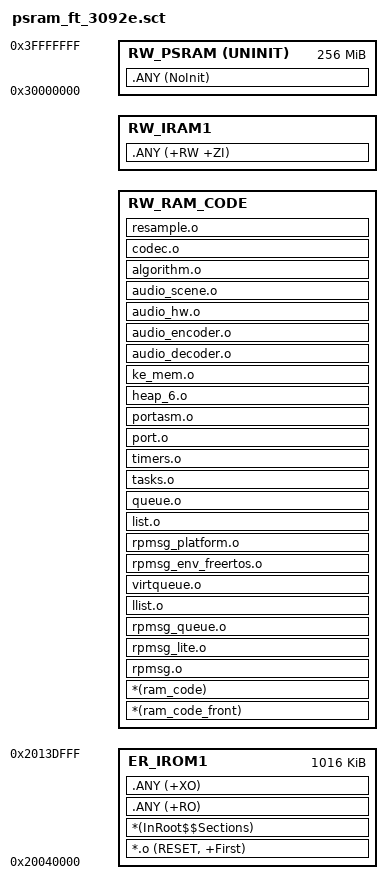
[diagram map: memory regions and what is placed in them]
; *************************************************************
; *** Scatter-Loading Description File generated by uVision ***
; *************************************************************

LR_IROM1 0x20040000 0x000FE000  {    ; load region size_region
  ER_IROM1 0x20040000 0x000FE000  {  ; load address = execution address
   *.o (RESET, +First)
   *(InRoot$$Sections)
   .ANY (+RO)
   .ANY (+XO)
  }
  RW_RAM_CODE +0 {
   *(ram_code_front)
   *(ram_code)
   rpmsg.o
   rpmsg_lite.o
   rpmsg_queue.o
   llist.o
   virtqueue.o
   rpmsg_env_freertos.o
   rpmsg_platform.o
   
   list.o
   queue.o
   tasks.o
   timers.o
   port.o
   portasm.o
   heap_6.o
   ke_mem.o
   
   audio_decoder.o
   audio_encoder.o
   audio_hw.o
   audio_scene.o
   algorithm.o
   codec.o
   resample.o
  }
  RW_IRAM1 +0  {  ; RW data
   .ANY (+RW +ZI)
  }
  RW_PSRAM 0x30000000 UNINIT 0x10000000 {  ; RW data
   .ANY (NoInit)
  }
}

